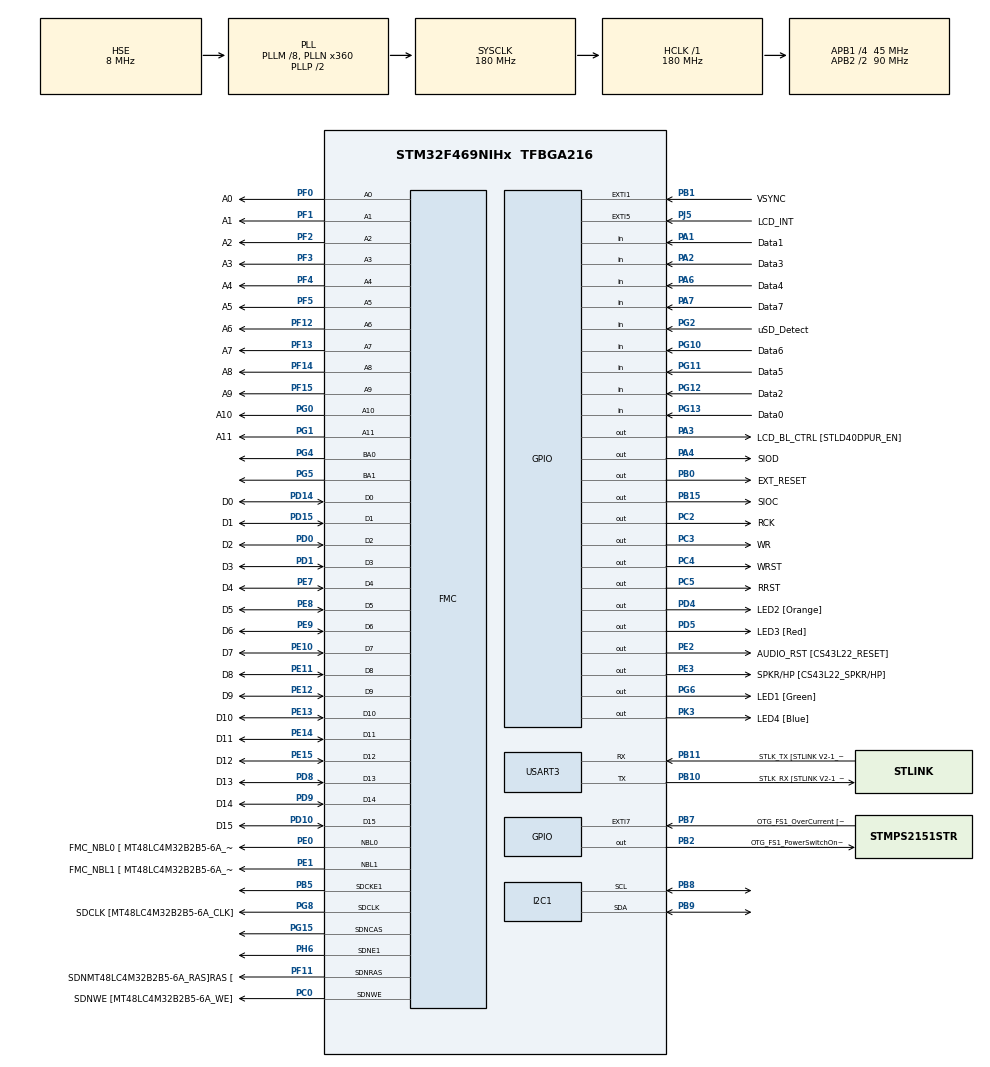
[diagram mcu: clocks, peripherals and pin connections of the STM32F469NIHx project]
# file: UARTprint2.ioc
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DSIHOST_CKN.GPIO_Label=DSI_CK_N
DSIHOST_CKN.Mode=DSIHost_Video
DSIHOST_CKN.Signal=DSIHOST_CKN
DSIHOST_CKP.GPIO_Label=DSI_CK_P
DSIHOST_CKP.Mode=DSIHost_Video
DSIHOST_CKP.Signal=DSIHOST_CKP
DSIHOST_D0N.GPIO_Label=DSI_D0_N
DSIHOST_D0N.Mode=DSIHost_Video
DSIHOST_D0N.Signal=DSIHOST_D0N
DSIHOST_D0P.GPIO_Label=DSI_D0_P
DSIHOST_D0P.Mode=DSIHost_Video
DSIHOST_D0P.Signal=DSIHOST_D0P
DSIHOST_D1N.GPIO_Label=DSI_D1_N
DSIHOST_D1N.Mode=DSIHost_Video
DSIHOST_D1N.Signal=DSIHOST_D1N
DSIHOST_D1P.GPIO_Label=DSI_D1_P
DSIHOST_D1P.Mode=DSIHost_Video
DSIHOST_D1P.Signal=DSIHOST_D1P
Mcu.Family=STM32F4
Mcu.Name=STM32F469NIHx
Mcu.Package=TFBGA216
NVIC.EXTI1_IRQn=true\:0\:0\:false\:false\:true\:true
NVIC.I2C1_EV_IRQn=true\:0\:0\:false\:false\:true\:true
NVIC.PriorityGroup=NVIC_PRIORITYGROUP_4
NVIC.USART3_IRQn=true\:0\:0\:false\:false\:true\:true
PA0/WKUP.GPIO_Label=WAKEUP [B2]
PA0/WKUP.Signal=SYS_WKUP
PA1.GPIO_Label=Data1
PA1.Signal=GPIO_Input
PA10.GPIO_Label=USB_FS1_ID
PA10.GPIO_Mode=GPIO_MODE_AF_PP
PA10.GPIO_PuPd=GPIO_NOPULL
PA10.GPIO_Speed=GPIO_SPEED_FREQ_VERY_HIGH
PA10.Signal=USB_OTG_FS_ID
PA11.GPIO_Label=USB_FS1_N
PA11.GPIO_Mode=GPIO_MODE_AF_PP
PA11.GPIO_PuPd=GPIO_NOPULL
PA11.GPIO_Speed=GPIO_SPEED_FREQ_VERY_HIGH
PA11.Signal=USB_OTG_FS_DM
PA12.GPIO_Label=USB_FS1_P
PA12.GPIO_Mode=GPIO_MODE_AF_PP
PA12.GPIO_PuPd=GPIO_NOPULL
PA12.GPIO_Speed=GPIO_SPEED_FREQ_VERY_HIGH
PA12.Signal=USB_OTG_FS_DP
PA13.GPIO_Label=SWDIO
PA13.Signal=SYS_JTMS-SWDIO
PA14.GPIO_Label=SWCLK
PA14.Signal=SYS_JTCK-SWCLK
PA2.GPIO_Label=Data3
PA2.Signal=GPIO_Input
PA3.GPIO_Label=LCD_BL_CTRL [STLD40DPUR_EN]
PA3.Signal=GPIO_Output
PA4.GPIO_Label=SIOD
PA4.GPIO_ModeDefaultOutputPP=GPIO_MODE_OUTPUT_OD
PA4.GPIO_PuPd=GPIO_PULLUP
PA4.GPIO_Speed=GPIO_SPEED_FREQ_HIGH
PA4.Signal=GPIO_Output
PA6.GPIO_Label=Data4
PA6.Signal=GPIO_Input
PA7.GPIO_Label=Data7
PA7.Signal=GPIO_Input
PA9.GPIO_Label=VBUS_FS1
PA9.GPIO_Mode=GPIO_MODE_AF_PP
PA9.GPIO_PuPd=GPIO_NOPULL
PA9.GPIO_Speed=GPIO_SPEED_FREQ_VERY_HIGH
PA9.Signal=USB_OTG_FS_VBUS
PB0.GPIO_Label=EXT_RESET
PB0.Signal=GPIO_Output
PB1.GPIO_Label=VSYNC
PB1.GPIO_ModeDefaultEXTI=GPIO_MODE_IT_FALLING
PB1.Signal=GPXTI1
PB10.GPIO_Label=STLK_RX [STLINK V2-1_U2_RX]
PB10.Mode=Asynchronous
PB10.Signal=USART3_TX
PB11.GPIO_Label=STLK_TX [STLINK V2-1_U2_TX]
PB11.Mode=Asynchronous
PB11.Signal=USART3_RX
PB15.GPIO_Label=SIOC
PB15.GPIO_ModeDefaultOutputPP=GPIO_MODE_OUTPUT_OD
PB15.GPIO_PuPd=GPIO_PULLUP
PB15.GPIO_Speed=GPIO_SPEED_FREQ_HIGH
PB15.Signal=GPIO_Output
PB2/BOOT1.GPIO_Label=OTG_FS1_PowerSwitchOn [STMPS2151STR_En]
PB2/BOOT1.Signal=GPIO_Output
PB3.GPIO_Label=I2S3_CK
PB3.GPIO_Mode=GPIO_MODE_AF_PP
PB3.GPIO_PuPd=GPIO_NOPULL
PB3.GPIO_Speed=GPIO_SPEED_FREQ_LOW
PB3.Signal=I2S3_CK
PB5.Mode=SdramChipSelect2_1
PB5.Signal=FMC_SDCKE1
PB6.GPIO_Label=QSPI_BK1_NCS [N25Q128A13EF840F_S]
PB6.GPIO_Mode=GPIO_MODE_AF_PP
PB6.GPIO_PuPd=GPIO_NOPULL
PB6.GPIO_Speed=GPIO_SPEED_FREQ_VERY_HIGH
PB6.Signal=QUADSPI_BK1_NCS
PB7.GPIO_Label=OTG_FS1_OverCurrent [STMPS2151STR_FAULT]
PB7.GPIO_ModeDefaultEXTI=GPIO_MODE_IT_RISING
PB7.GPIO_PuPd=GPIO_NOPULL
PB7.Signal=GPXTI7
PB8.Mode=I2C
PB8.Signal=I2C1_SCL
PB9.Mode=I2C
PB9.Signal=I2C1_SDA
PC0.GPIO_Label=SDNWE [MT48LC4M32B2B5-6A_WE]
PC0.Signal=FMC_SDNWE
PC10.GPIO_Label=uSD_D2
PC10.GPIO_Mode=GPIO_MODE_AF_PP
PC10.GPIO_PuPd=GPIO_NOPULL
PC10.GPIO_Speed_High_Default=GPIO_SPEED_FREQ_VERY_HIGH
PC10.Signal=SDIO_D2
PC11.GPIO_Label=uSD_D3
PC11.GPIO_Mode=GPIO_MODE_AF_PP
PC11.GPIO_PuPd=GPIO_NOPULL
PC11.GPIO_Speed_High_Default=GPIO_SPEED_FREQ_VERY_HIGH
PC11.Signal=SDIO_D3
PC12.GPIO_Label=uSD_CLK
PC12.GPIO_Mode=GPIO_MODE_AF_PP
PC12.GPIO_PuPd=GPIO_NOPULL
PC12.GPIO_Speed_High_Default=GPIO_SPEED_FREQ_VERY_HIGH
PC12.Signal=SDIO_CK
PC14/OSC32_IN.Signal=RCC_OSC32_IN
PC15/OSC32_OUT.Signal=RCC_OSC32_OUT
PC2.GPIO_Label=RCK
PC2.GPIO_Speed=GPIO_SPEED_FREQ_HIGH
PC2.Signal=GPIO_Output
PC3.GPIO_Label=WR
PC3.GPIO_Speed=GPIO_SPEED_FREQ_HIGH
PC3.Signal=GPIO_Output
PC4.GPIO_Label=WRST
PC4.GPIO_Speed=GPIO_SPEED_FREQ_HIGH
PC4.Signal=GPIO_Output
PC5.GPIO_Label=RRST
PC5.GPIO_Speed=GPIO_SPEED_FREQ_HIGH
PC5.Signal=GPIO_Output
PC8.GPIO_Label=uSD_D0
PC8.GPIO_Mode=GPIO_MODE_AF_PP
PC8.GPIO_PuPd=GPIO_NOPULL
PC8.GPIO_Speed_High_Default=GPIO_SPEED_FREQ_VERY_HIGH
PC8.Signal=SDIO_D0
PC9.GPIO_Label=uSD_D1
PC9.GPIO_Mode=GPIO_MODE_AF_PP
PC9.GPIO_PuPd=GPIO_NOPULL
PC9.GPIO_Speed_High_Default=GPIO_SPEED_FREQ_VERY_HIGH
PC9.Signal=SDIO_D1
PD0.GPIO_Label=D2
PD0.GPIO_Mode=GPIO_MODE_AF_PP
PD0.GPIO_PuPd=GPIO_NOPULL
PD0.GPIO_Speed_High_Default=GPIO_SPEED_FREQ_VERY_HIGH
PD0.Signal=FMC_D2_DA2
PD1.GPIO_Label=D3
PD1.GPIO_Mode=GPIO_MODE_AF_PP
PD1.GPIO_PuPd=GPIO_NOPULL
PD1.GPIO_Speed_High_Default=GPIO_SPEED_FREQ_VERY_HIGH
PD1.Signal=FMC_D3_DA3
PD10.GPIO_Label=D15
PD10.Signal=FMC_D15_DA15
PD13.GPIO_Label=MIC_CK [MP34DT01TR_CLK]
PD13.Signal=S_TIM4_CH2
PD14.GPIO_Label=D0
PD14.Signal=FMC_D0_DA0
PD15.GPIO_Label=D1
PD15.Signal=FMC_D1_DA1
PD2.GPIO_Label=uSD_CMD
PD2.GPIO_Mode=GPIO_MODE_AF_PP
PD2.GPIO_PuPd=GPIO_NOPULL
PD2.GPIO_Speed_High_Default=GPIO_SPEED_FREQ_VERY_HIGH
PD2.Signal=SDIO_CMD
PD4.GPIO_Label=LED2 [Orange]
PD4.GPIO_ModeDefaultOutputPP=GPIO_MODE_OUTPUT_OD
PD4.GPIO_PuPd=GPIO_NOPULL
PD4.GPIO_Speed=GPIO_SPEED_FREQ_LOW
PD4.Signal=GPIO_Output
PD5.GPIO_Label=LED3 [Red]
PD5.GPIO_ModeDefaultOutputPP=GPIO_MODE_OUTPUT_OD
PD5.GPIO_PuPd=GPIO_NOPULL
PD5.GPIO_Speed=GPIO_SPEED_FREQ_LOW
PD5.Signal=GPIO_Output
PD6.GPIO_Label=MIC_DATA [MP34DT01TR_DOUT]
PD6.GPIO_Mode=GPIO_MODE_AF_PP
PD6.GPIO_PuPd=GPIO_NOPULL
PD6.GPIO_Speed=GPIO_SPEED_FREQ_LOW
PD6.Signal=SAI1_SD_A
PD8.GPIO_Label=D13
PD8.Signal=FMC_D13_DA13
PD9.GPIO_Label=D14
PD9.Signal=FMC_D14_DA14
PE0.GPIO_Label=FMC_NBL0 [ MT48LC4M32B2B5-6A_DQM0]
PE0.GPIO_Mode=GPIO_MODE_AF_PP
PE0.GPIO_PuPd=GPIO_NOPULL
PE0.GPIO_Speed_High_Default=GPIO_SPEED_FREQ_VERY_HIGH
PE0.Signal=FMC_NBL0
PE1.GPIO_Label=FMC_NBL1 [ MT48LC4M32B2B5-6A_DQM1]
PE1.GPIO_Mode=GPIO_MODE_AF_PP
PE1.GPIO_PuPd=GPIO_NOPULL
PE1.GPIO_Speed_High_Default=GPIO_SPEED_FREQ_VERY_HIGH
PE1.Signal=FMC_NBL1
PE10.GPIO_Label=D7
PE10.Signal=FMC_D7_DA7
PE11.GPIO_Label=D8
PE11.Signal=FMC_D8_DA8
PE12.GPIO_Label=D9
PE12.Signal=FMC_D9_DA9
PE13.GPIO_Label=D10
PE13.Signal=FMC_D10_DA10
PE14.GPIO_Label=D11
PE14.Signal=FMC_D11_DA11
PE15.GPIO_Label=D12
PE15.Signal=FMC_D12_DA12
PE2.GPIO_Label=AUDIO_RST [CS43L22_RESET]
PE2.GPIO_ModeDefaultOutputPP=GPIO_MODE_OUTPUT_PP
PE2.GPIO_PuPd=GPIO_NOPULL
PE2.GPIO_Speed=GPIO_SPEED_FREQ_LOW
PE2.Signal=GPIO_Output
PE3.GPIO_Label=SPKR/HP [CS43L22_SPKR/HP]
PE3.GPIO_ModeDefaultOutputPP=GPIO_MODE_OUTPUT_PP
PE3.GPIO_PuPd=GPIO_NOPULL
PE3.GPIO_Speed=GPIO_SPEED_FREQ_LOW
PE3.Signal=GPIO_Output
PE4.GPIO_Label=SAI1_FSA [CS43L22_LRCK]
PE4.GPIO_Mode=GPIO_MODE_AF_PP
PE4.GPIO_PuPd=GPIO_NOPULL
PE4.GPIO_Speed=GPIO_SPEED_FREQ_LOW
PE4.Signal=SAI1_FS_A
PE5.GPIO_Label=SAI1_SCKA [CS43L22_CLK]
PE5.GPIO_Mode=GPIO_MODE_AF_PP
PE5.GPIO_PuPd=GPIO_NOPULL
PE5.GPIO_Speed=GPIO_SPEED_FREQ_LOW
PE5.Signal=SAI1_SCK_A
PE7.GPIO_Label=D4
PE7.Signal=FMC_D4_DA4
PE8.GPIO_Label=D5
PE8.Signal=FMC_D5_DA5
PE9.GPIO_Label=D6
PE9.Signal=FMC_D6_DA6
PF0.GPIO_Label=A0
PF0.GPIO_Mode=GPIO_MODE_AF_PP
PF0.GPIO_PuPd=GPIO_NOPULL
PF0.GPIO_Speed_High_Default=GPIO_SPEED_FREQ_VERY_HIGH
PF0.Signal=FMC_A0
PF1.GPIO_Label=A1
PF1.GPIO_Mode=GPIO_MODE_AF_PP
PF1.GPIO_PuPd=GPIO_NOPULL
PF1.GPIO_Speed_High_Default=GPIO_SPEED_FREQ_VERY_HIGH
PF1.Signal=FMC_A1
PF10.GPIO_Label=QSPI_CLK [N25Q128A13EF840F_C]
PF10.Signal=QUADSPI_CLK
PF11.GPIO_Label=SDNMT48LC4M32B2B5-6A_RAS]RAS [
PF11.Signal=FMC_SDNRAS
PF12.GPIO_Label=A6
PF12.Signal=FMC_A6
PF13.GPIO_Label=A7
PF13.Signal=FMC_A7
PF14.GPIO_Label=A8
PF14.Signal=FMC_A8
PF15.GPIO_Label=A9
PF15.Signal=FMC_A9
PF2.GPIO_Label=A2
PF2.GPIO_Mode=GPIO_MODE_AF_PP
PF2.GPIO_PuPd=GPIO_NOPULL
PF2.GPIO_Speed_High_Default=GPIO_SPEED_FREQ_VERY_HIGH
PF2.Signal=FMC_A2
PF3.GPIO_Label=A3
PF3.GPIO_Mode=GPIO_MODE_AF_PP
PF3.GPIO_PuPd=GPIO_NOPULL
PF3.GPIO_Speed_High_Default=GPIO_SPEED_FREQ_VERY_HIGH
PF3.Signal=FMC_A3
PF4.GPIO_Label=A4
PF4.GPIO_Mode=GPIO_MODE_AF_PP
PF4.GPIO_PuPd=GPIO_NOPULL
PF4.GPIO_Speed_High_Default=GPIO_SPEED_FREQ_VERY_HIGH
PF4.Signal=FMC_A4
PF5.GPIO_Label=A5
PF5.Signal=FMC_A5
PF6.GPIO_Label=QSPI_BK1_IO3 [N25Q128A13EF840F_DQ3]
PF6.Signal=QUADSPI_BK1_IO3
PF7.GPIO_Label=QSPI_BK1_IO2 [N25Q128A13EF840F_DQ2]
PF7.Signal=QUADSPI_BK1_IO2
PF8.GPIO_Label=QSPI_BK1_IO0 [N25Q128A13EF840F_DQ0]
PF8.Signal=QUADSPI_BK1_IO0
PF9.GPIO_Label=QSPI_BK1_IO1 [N25Q128A13EF840F_DQ1]
PF9.Signal=QUADSPI_BK1_IO1
PG0.GPIO_Label=A10
PG0.Signal=FMC_A10
PG1.GPIO_Label=A11
PG1.Signal=FMC_A11
PG10.GPIO_Label=Data6
PG10.Signal=GPIO_Input
PG11.GPIO_Label=Data5
PG11.Signal=GPIO_Input
PG12.GPIO_Label=Data2
PG12.Signal=GPIO_Input
PG13.GPIO_Label=Data0
PG13.Signal=GPIO_Input
PG14.GPIO_Label=ARDUINO USART6_TX
PG14.GPIO_Mode=GPIO_MODE_AF_PP
PG14.GPIO_PuPd=GPIO_NOPULL
PG14.GPIO_Speed=GPIO_SPEED_FREQ_VERY_HIGH
PG14.Signal=USART6_TX
PG15.Signal=FMC_SDNCAS
PG2.GPIO_Label=uSD_Detect
PG2.Signal=GPIO_Input
PG4.Signal=FMC_A14_BA0
PG5.Signal=FMC_A15_BA1
PG6.GPIO_Label=LED1 [Green]
PG6.GPIO_ModeDefaultOutputPP=GPIO_MODE_OUTPUT_OD
PG6.GPIO_PuPd=GPIO_NOPULL
PG6.GPIO_Speed=GPIO_SPEED_FREQ_LOW
PG6.Signal=GPIO_Output
PG7.GPIO_Label=SAI1_MCLKA [CS43L22_MCLK]
PG7.GPIO_Mode=GPIO_MODE_AF_PP
PG7.GPIO_PuPd=GPIO_NOPULL
PG7.GPIO_Speed=GPIO_SPEED_FREQ_LOW
PG7.Signal=SAI1_MCLK_A
PG8.GPIO_Label=SDCLK [MT48LC4M32B2B5-6A_CLK]
PG8.GPIO_Mode=GPIO_MODE_AF_PP
PG8.GPIO_PuPd=GPIO_NOPULL
PG8.GPIO_Speed_High_Default=GPIO_SPEED_FREQ_VERY_HIGH
PG8.Signal=FMC_SDCLK
PG9.GPIO_Label=USART6_RX
PG9.GPIO_Mode=GPIO_MODE_AF_PP
PG9.GPIO_PuPd=GPIO_NOPULL
PG9.GPIO_Speed=GPIO_SPEED_FREQ_VERY_HIGH
PG9.Signal=USART6_RX
PH0/OSC_IN.Mode=HSE-External-Oscillator
PH0/OSC_IN.Signal=RCC_OSC_IN
PH1/OSC_OUT.Mode=HSE-External-Oscillator
PH1/OSC_OUT.Signal=RCC_OSC_OUT
PH10.GPIO_Label=D18
PH10.Signal=FMC_D18
PH11.GPIO_Label=D19
PH11.Signal=FMC_D19
PH12.GPIO_Label=D20
PH12.Signal=FMC_D20
PH13.GPIO_Label=D21
PH13.GPIO_Mode=GPIO_MODE_AF_PP
PH13.GPIO_PuPd=GPIO_NOPULL
PH13.GPIO_Speed_High_Default=GPIO_SPEED_FREQ_VERY_HIGH
PH13.Signal=FMC_D21
PH14.GPIO_Label=D22
PH14.GPIO_Mode=GPIO_MODE_AF_PP
PH14.GPIO_PuPd=GPIO_NOPULL
PH14.GPIO_Speed_High_Default=GPIO_SPEED_FREQ_VERY_HIGH
PH14.Signal=FMC_D22
PH15.GPIO_Label=D23
PH15.GPIO_Mode=GPIO_MODE_AF_PP
PH15.GPIO_PuPd=GPIO_NOPULL
PH15.GPIO_Speed_High_Default=GPIO_SPEED_FREQ_VERY_HIGH
PH15.Signal=FMC_D23
PH2.GPIO_Label=SDCKE0 [MT48LC4M32B2B5-6A_CKE]
PH2.Signal=FMC_SDCKE0
PH3.GPIO_Label=SDNE0 [MT48LC4M32B2B5-6A_CS]
PH3.GPIO_Mode=GPIO_MODE_AF_PP
PH3.GPIO_PuPd=GPIO_NOPULL
PH3.GPIO_Speed_High_Default=GPIO_SPEED_FREQ_VERY_HIGH
PH3.Signal=FMC_SDNE0
PH4.GPIO_Label=I2C2_SCL [CS43L22_SCL]
PH4.GPIO_Mode=GPIO_MODE_AF_OD
PH4.GPIO_PuPdOD=GPIO_PULLUP
PH4.GPIO_Speed=GPIO_SPEED_FREQ_VERY_HIGH
PH4.Signal=I2C2_SCL
PH5.GPIO_Label=I2C2_SDA [CS43L22_SDA]
PH5.GPIO_Mode=GPIO_MODE_AF_OD
PH5.GPIO_PuPdOD=GPIO_PULLUP
PH5.GPIO_Speed=GPIO_SPEED_FREQ_VERY_HIGH
PH5.Signal=I2C2_SDA
PH6.Mode=SdramChipSelect2_1
PH6.Signal=FMC_SDNE1
PH8.GPIO_Label=D16
PH8.Signal=FMC_D16
PH9.GPIO_Label=D17
PH9.Signal=FMC_D17
PI0.GPIO_Label=D24
PI0.GPIO_Mode=GPIO_MODE_AF_PP
PI0.GPIO_PuPd=GPIO_NOPULL
PI0.GPIO_Speed_High_Default=GPIO_SPEED_FREQ_VERY_HIGH
PI0.Signal=FMC_D24
PI1.GPIO_Label=D25
PI1.GPIO_Mode=GPIO_MODE_AF_PP
PI1.GPIO_PuPd=GPIO_NOPULL
PI1.GPIO_Speed_High_Default=GPIO_SPEED_FREQ_VERY_HIGH
PI1.Signal=FMC_D25
PI10.GPIO_Label=D31
PI10.GPIO_Mode=GPIO_MODE_AF_PP
PI10.GPIO_PuPd=GPIO_NOPULL
PI10.GPIO_Speed_High_Default=GPIO_SPEED_FREQ_VERY_HIGH
PI10.Signal=FMC_D31
PI2.GPIO_Label=D26
PI2.GPIO_Mode=GPIO_MODE_AF_PP
PI2.GPIO_PuPd=GPIO_NOPULL
PI2.GPIO_Speed_High_Default=GPIO_SPEED_FREQ_VERY_HIGH
PI2.Signal=FMC_D26
PI3.GPIO_Label=D27
PI3.GPIO_Mode=GPIO_MODE_AF_PP
PI3.GPIO_PuPd=GPIO_NOPULL
PI3.GPIO_Speed_High_Default=GPIO_SPEED_FREQ_VERY_HIGH
PI3.Signal=FMC_D27
PI4.GPIO_Label=FMC_NBL2 [MT48LC4M32B2B5-6A_DQM2]
PI4.GPIO_Mode=GPIO_MODE_AF_PP
PI4.GPIO_PuPd=GPIO_NOPULL
PI4.GPIO_Speed_High_Default=GPIO_SPEED_FREQ_VERY_HIGH
PI4.Signal=FMC_NBL2
PI5.GPIO_Label=FMC_NBL3 [MT48LC4M32B2B5-6A_DQM3]
PI5.GPIO_Mode=GPIO_MODE_AF_PP
PI5.GPIO_PuPd=GPIO_NOPULL
PI5.GPIO_Speed_High_Default=GPIO_SPEED_FREQ_VERY_HIGH
PI5.Signal=FMC_NBL3
PI6.GPIO_Label=D28
PI6.GPIO_Mode=GPIO_MODE_AF_PP
PI6.GPIO_PuPd=GPIO_NOPULL
PI6.GPIO_Speed_High_Default=GPIO_SPEED_FREQ_VERY_HIGH
PI6.Signal=FMC_D28
PI7.GPIO_Label=D29
PI7.GPIO_Mode=GPIO_MODE_AF_PP
PI7.GPIO_PuPd=GPIO_NOPULL
PI7.GPIO_Speed_High_Default=GPIO_SPEED_FREQ_VERY_HIGH
PI7.Signal=FMC_D29
PI9.GPIO_Label=D30
PI9.GPIO_Mode=GPIO_MODE_AF_PP
PI9.GPIO_PuPd=GPIO_NOPULL
PI9.GPIO_Speed_High_Default=GPIO_SPEED_FREQ_VERY_HIGH
PI9.Signal=FMC_D30
PJ2.GPIO_Label=DSI_TE
PJ2.Signal=DSIHOST_TE
PJ5.GPIO_Label=LCD_INT
PJ5.Signal=GPXTI5
PK3.GPIO_Label=LED4 [Blue]
PK3.GPIO_ModeDefaultOutputPP=GPIO_MODE_OUTPUT_OD
PK3.GPIO_PuPd=GPIO_NOPULL
PK3.GPIO_Speed=GPIO_SPEED_FREQ_LOW
PK3.Signal=GPIO_Output
ProjectManager.HeapSize=0x200
ProjectManager.StackSize=0x400
ProjectManager.TargetToolchain=MDK-ARM V5
RCC.AHBFreq_Value=180000000
RCC.APB1CLKDivider=RCC_HCLK_DIV4
RCC.APB1Freq_Value=45000000
RCC.APB1TimFreq_Value=90000000
RCC.APB2CLKDivider=RCC_HCLK_DIV2
RCC.APB2Freq_Value=90000000
RCC.APB2TimFreq_Value=180000000
RCC.CortexFreq_Value=180000000
RCC.HCLKFreq_Value=180000000
RCC.HSE_VALUE=8000000
RCC.PLLDSINDIV=62
RCC.PLLM=8
RCC.PLLN=360
RCC.PLLSourceVirtual=RCC_PLLSOURCE_HSE
RCC.SYSCLKFreq_VALUE=180000000
RCC.SYSCLKSource=RCC_SYSCLKSOURCE_PLLCLK
RCC.USBFreq_Value=90000000
RCC.VCOOutputFreq_Value=360000000
SH.FMC_A0.0=FMC_A0,12b-sda1
SH.FMC_A1.0=FMC_A1,12b-sda1
SH.FMC_A10.0=FMC_A10,12b-sda1
SH.FMC_A11.0=FMC_A11,12b-sda1
SH.FMC_A14_BA0.0=FMC_BA0,FourSdramBanks1
SH.FMC_A15_BA1.0=FMC_BA1,FourSdramBanks1
SH.FMC_A2.0=FMC_A2,12b-sda1
SH.FMC_A3.0=FMC_A3,12b-sda1
SH.FMC_A4.0=FMC_A4,12b-sda1
SH.FMC_A5.0=FMC_A5,12b-sda1
SH.FMC_A6.0=FMC_A6,12b-sda1
SH.FMC_A7.0=FMC_A7,12b-sda1
SH.FMC_A8.0=FMC_A8,12b-sda1
SH.FMC_A9.0=FMC_A9,12b-sda1
SH.FMC_D0_DA0.0=FMC_D0,sd-16b-d1
SH.FMC_D10_DA10.0=FMC_D10,sd-16b-d1
SH.FMC_D11_DA11.0=FMC_D11,sd-16b-d1
SH.FMC_D12_DA12.0=FMC_D12,sd-16b-d1
SH.FMC_D13_DA13.0=FMC_D13,sd-16b-d1
SH.FMC_D14_DA14.0=FMC_D14,sd-16b-d1
SH.FMC_D15_DA15.0=FMC_D15,sd-16b-d1
SH.FMC_D16.0=FMC_D16
SH.FMC_D17.0=FMC_D17
SH.FMC_D18.0=FMC_D18
SH.FMC_D19.0=FMC_D19
SH.FMC_D1_DA1.0=FMC_D1,sd-16b-d1
SH.FMC_D20.0=FMC_D20
SH.FMC_D21.0=FMC_D21
SH.FMC_D22.0=FMC_D22
SH.FMC_D23.0=FMC_D23
SH.FMC_D24.0=FMC_D24
SH.FMC_D25.0=FMC_D25
SH.FMC_D26.0=FMC_D26
SH.FMC_D27.0=FMC_D27
SH.FMC_D28.0=FMC_D28
SH.FMC_D29.0=FMC_D29
SH.FMC_D2_DA2.0=FMC_D2,sd-16b-d1
SH.FMC_D30.0=FMC_D30
SH.FMC_D31.0=FMC_D31
SH.FMC_D3_DA3.0=FMC_D3,sd-16b-d1
SH.FMC_D4_DA4.0=FMC_D4,sd-16b-d1
SH.FMC_D5_DA5.0=FMC_D5,sd-16b-d1
SH.FMC_D6_DA6.0=FMC_D6,sd-16b-d1
SH.FMC_D7_DA7.0=FMC_D7,sd-16b-d1
SH.FMC_D8_DA8.0=FMC_D8,sd-16b-d1
SH.FMC_D9_DA9.0=FMC_D9,sd-16b-d1
SH.FMC_NBL0.0=FMC_NBL0,Sd2ByteEnable1
SH.FMC_NBL1.0=FMC_NBL1,Sd2ByteEnable1
SH.FMC_NBL2.0=FMC_NBL2
SH.FMC_NBL3.0=FMC_NBL3
SH.FMC_SDCLK.0=FMC_SDCLK,12b-sda1
SH.FMC_SDNCAS.0=FMC_SDNCAS,12b-sda1
SH.FMC_SDNRAS.0=FMC_SDNRAS,12b-sda1
SH.FMC_SDNWE.0=FMC_SDNWE,12b-sda1
SH.S_TIM4_CH2.0=TIM4_CH2
USART3.VirtualMode=VM_ASYNC
VP_DMA2D_VS_DMA2D.Mode=DMA2D_Activate
VP_LTDC_DSIMode.Mode=RGB565
board=32F469IDISCOVERY

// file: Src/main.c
/**
  ******************************************************************************
  * @file           : main.c
  * @brief          : Main program body
  ******************************************************************************
  ** This notice applies to any and all portions of this file
  * that are not between comment pairs USER CODE BEGIN and
  * USER CODE END. Other portions of this file, whether
  * inserted by the user or by software development tools
  * are owned by their respective copyright owners.
  *
  * COPYRIGHT(c) 2018 STMicroelectronics
  *
  * Redistribution and use in source and binary forms, with or without modification,
  * are permitted provided that the following conditions are met:
  *   1. Redistributions of source code must retain the above copyright notice,
  *      this list of conditions and the following disclaimer.
  *   2. Redistributions in binary form must reproduce the above copyright notice,
  *      this list of conditions and the following disclaimer in the documentation
  *      and/or other materials provided with the distribution.
  *   3. Neither the name of STMicroelectronics nor the names of its contributors
  *      may be used to endorse or promote products derived from this software
  *      without specific prior written permission.
  *
  * THIS SOFTWARE IS PROVIDED BY THE COPYRIGHT HOLDERS AND CONTRIBUTORS "AS IS"
  * AND ANY EXPRESS OR IMPLIED WARRANTIES, INCLUDING, BUT NOT LIMITED TO, THE
  * IMPLIED WARRANTIES OF MERCHANTABILITY AND FITNESS FOR A PARTICULAR PURPOSE ARE
  * DISCLAIMED. IN NO EVENT SHALL THE COPYRIGHT HOLDER OR CONTRIBUTORS BE LIABLE
  * FOR ANY DIRECT, INDIRECT, INCIDENTAL, SPECIAL, EXEMPLARY, OR CONSEQUENTIAL
  * DAMAGES (INCLUDING, BUT NOT LIMITED TO, PROCUREMENT OF SUBSTITUTE GOODS OR
  * SERVICES; LOSS OF USE, DATA, OR PROFITS; OR BUSINESS INTERRUPTION) HOWEVER
  * CAUSED AND ON ANY THEORY OF LIABILITY, WHETHER IN CONTRACT, STRICT LIABILITY,
  * OR TORT (INCLUDING NEGLIGENCE OR OTHERWISE) ARISING IN ANY WAY OUT OF THE USE
  * OF THIS SOFTWARE, EVEN IF ADVISED OF THE POSSIBILITY OF SUCH DAMAGE.
  *
  ******************************************************************************
  */
#include "main.h"
#include "stm32f4xx_hal.h"

/* USER CODE BEGIN Includes */
#include "stm32469i_discovery.h"
#include "stm32469i_discovery_lcd.h"
#include "SCCB.h"
#include "OV7670.h"

/* USER CODE END Includes */

DMA2D_HandleTypeDef hdma2d;

DSI_HandleTypeDef hdsi;

I2C_HandleTypeDef hi2c1;

LTDC_HandleTypeDef hltdc;

UART_HandleTypeDef huart3;

SDRAM_HandleTypeDef hsdram1;

/* USER CODE BEGIN PV */
/* Private variables ---------------------------------------------------------*/

/* USER CODE END PV */

void SystemClock_Config(void);
static void MX_GPIO_Init(void);
static void MX_USART3_UART_Init(void);
static void MX_I2C1_Init(void);
static void MX_LTDC_Init(void);
static void MX_DMA2D_Init(void);
static void MX_DSIHOST_DSI_Init(void);
static void MX_FMC_Init(void);

/* USER CODE BEGIN PFP */
/* Private function prototypes -----------------------------------------------*/

/* USER CODE END PFP */

/* USER CODE BEGIN 0 */
uint32_t count=0;
uint32_t vsyncCount=(uint32_t)'0';
uint32_t vsyncStatus=0;
uint32_t photoTakeTimeStart=0;
uint32_t photoTakeTimeEnd=0;
uint32_t photoTakeTimeElapse=0;
char photoTakeTimeElapseHex[6];
uint8_t Data[8];
/**
  * @brief  Retargets the C library printf function to the UART.
	* @param  None
	* @retval None
  */
#ifdef __GNUC__
	#define PUTCHAR_PROTOTYPE int __io_putchar(int ch)
#else
	#define PUTCHAR_PROTOTYPE int fputc(int ch, FILE *f)
#endif

PUTCHAR_PROTOTYPE
{
	HAL_UART_Transmit(&huart3, (uint8_t *)&ch, 1, 0xFFFF);
	return ch;
}

/* USER CODE END 0 */

int main(void)
{

  /* MCU Configuration----------------------------------------------------------*/

  /* Reset of all peripherals, Initializes the Flash interface and the Systick. */
  HAL_Init();

  /* USER CODE BEGIN Init */

	BSP_LED_Init(LED1);
	BSP_LED_Init(LED2);
	BSP_LED_Init(LED3);
	BSP_LED_Init(LED4);

  /* USER CODE END Init */

  /* Configure the system clock */
  SystemClock_Config();

  /* USER CODE BEGIN SysInit */
	uint8_t Container[2] = {0x44, 0xAA};
	char ContainerInHex[2];
  /* USER CODE END SysInit */

  /* Initialize all configured peripherals */
  MX_GPIO_Init();
  MX_USART3_UART_Init();
  MX_I2C1_Init();
  MX_LTDC_Init();
  MX_DMA2D_Init();
  MX_DSIHOST_DSI_Init();
  MX_FMC_Init();
  /* USER CODE BEGIN 2 */
	I2C_WriteByte(0x12, 0x80, ADDR_OV7670);
	HAL_Delay(50);
//	I2C_WriteByte(0x12, 0x14, ADDR_OV7670);
	HAL_Delay(50);
	//Sensor_Init();

	I2C_ReadByte(Container, 1, 0x12, ADDR_OV7670);
	printf("0x12:%X\n\r", Container[0]);

	for(uint8_t i=0; i<202; i++)
	{
		I2C_ReadByte(Container, 1, i, ADDR_OV7670);
		printf("%X:%X\n\r",i, Container[0]);
		HAL_Delay(10);
	}
	BSP_LCD_Init();
	BSP_LCD_LayerDefaultInit(0, LCD_FB_START_ADDRESS);
	BSP_LCD_SelectLayer(0);
	BSP_LCD_Clear(LCD_COLOR_WHITE);

	//WE_H();

	WRST_H();
	RRST_H();

  /* USER CODE END 2 */

  /* Infinite loop */
  while (1)
  {

  /* USER CODE BEGIN 3 */
//		I2C_ReadByte(Container, 1, 0x11, ADDR_OV7670);
//		HAL_Delay(100);
//		HAL_UART_Transmit(&huart3, (uint8_t*) "It's Working", 12, 0XFFFF);
//		ContainerInHex[0]=Container[0]/16+'0';
//		ContainerInHex[1]=Container[0]%16+'0';
//		HAL_UART_Transmit(&huart3, (uint8_t*)ContainerInHex, 2, 0xFFFF);
//		HAL_UART_Transmit(&huart3, (uint8_t*) "\r\n", 4, 0xFFFF);
//		HAL_UART_Transmit(&huart3, (uint8_t*)&vsyncCount, 1, 0xFFFF);
//		HAL_UART_Transmit(&huart3, (uint8_t*) "\r\n", 4, 0xFFFF);
//		for(int i=5; i>=0; i--)
//		{
//			photoTakeTimeElapseHex[i]=photoTakeTimeElapse%16+'0';
//			photoTakeTimeElapse/=16;
//		}
//		if(vsyncStatus==1) HAL_UART_Transmit(&huart3, (uint8_t*)"Interrupted\r\n", 15, 0xFFFF);

//		HAL_UART_Transmit(&huart3, (uint8_t*)photoTakeTimeElapseHex, 6, 0xFFFF);
//		HAL_UART_Transmit(&huart3, (uint8_t*) "\r\n", 4, 0xFFFF);

		if( vsyncStatus == 2 )
		{
//			HAL_UART_Transmit(&huart3, (uint8_t*)"It can turn into 2\n\r", 22, 0xFFFF);
			//WE_L();
			RRST_L();
			RCLK_L();

			for(int i=0; i<100	; i++);

			RCLK_H();
			RRST_H();
			RCLK_L();
			for(int i=0; i<100; i++);

			RCLK_H();
			for(int i=0; i<100; i++);

//			for( count = 0; count < 76800; count++ )
//			{
			for(int yAxis=0; yAxis<240; yAxis++)
			{
				for(int xAxis=0; xAxis<320; xAxis++)
				{
					RCLK_L();

					uint8_t tmpData = 0x00;
					uint32_t redVal=0x00, greenVal=0x00, blueVal=0x00;
					uint8_t tmpDataHex[2];
					uint32_t mixed=0xFF000000;

					redVal |=	 ((Data3_GPIO_Port->IDR & Data3_Pin)>>2)
										|((Data4_GPIO_Port->IDR & Data4_Pin)>>5)
										|((Data5_GPIO_Port->IDR & Data5_Pin)>>9)
										|((Data3_GPIO_Port->IDR & Data3_Pin)<<1)
										|((Data4_GPIO_Port->IDR & Data4_Pin)>>2)
										|((Data5_GPIO_Port->IDR & Data5_Pin)>>6)
										|((Data6_GPIO_Port->IDR & Data6_Pin)>>4)
										|((Data7_GPIO_Port->IDR & Data7_Pin));

					greenVal |=	 (Data0_GPIO_Port->IDR & Data0_Pin>>8)
											|((Data1_GPIO_Port->IDR & Data1_Pin)<<5)
											|((Data2_GPIO_Port->IDR & Data2_Pin)>>5);

	//				tmpData |= (Data0_GPIO_Port->IDR & Data0_Pin>>13)
	//									|((Data1_GPIO_Port->IDR & Data1_Pin))
	//									|((Data2_GPIO_Port->IDR & Data2_Pin)>>10)
	//									|((Data3_GPIO_Port->IDR & Data3_Pin)<<1)
	//									|((Data4_GPIO_Port->IDR & Data4_Pin)>>2)
	//									|((Data5_GPIO_Port->IDR & Data5_Pin)>>6)
	//									|((Data6_GPIO_Port->IDR & Data6_Pin)>>4)
	//									|((Data7_GPIO_Port->IDR & Data7_Pin));	  /* ( GPIO_ReadInputData(GPIOC) << 8 ) & 0xff00; */

	//				printf("1:");
	//				if(Data0_GPIO_Port->IDR&Data0_Pin) printf("1"); else printf("0");
	//				if(Data1_GPIO_Port->IDR&Data1_Pin) printf("1"); else printf("0");
	//				if(Data2_GPIO_Port->IDR&Data2_Pin) printf("1"); else printf("0");
	//				if(Data3_GPIO_Port->IDR&Data3_Pin) printf("1"); else printf("0");
	//				if(Data4_GPIO_Port->IDR&Data4_Pin) printf("1"); else printf("0");
	//				if(Data5_GPIO_Port->IDR&Data5_Pin) printf("1"); else printf("0");
	//				if(Data6_GPIO_Port->IDR&Data6_Pin) printf("1"); else printf("0");
	//				if(Data7_GPIO_Port->IDR&Data7_Pin) printf("1"); else printf("0");
	//				printf("\r\n");
					RCLK_H();

	//				tmpDataHex[0]=tmpData/16+'0';
	//				tmpDataHex[1]=tmpData%16+'0';
					//HAL_UART_Transmit(&huart3, tmpDataHex, 2, 0xFFFF);
					for(int i=0; i<100; i++);

					RCLK_L();
	//				tmpData=0x00;
	//				tmpData |= (Data0_GPIO_Port->IDR & Data0_Pin>>13)
	//									|((Data1_GPIO_Port->IDR & Data1_Pin))
	//									|((Data2_GPIO_Port->IDR & Data2_Pin)>>10)
	//									|((Data3_GPIO_Port->IDR & Data3_Pin)<<1)
	//									|((Data4_GPIO_Port->IDR & Data4_Pin)>>2)
	//									|((Data5_GPIO_Port->IDR & Data5_Pin)>>6)
	//									|((Data6_GPIO_Port->IDR & Data6_Pin)>>4)
	//									|((Data7_GPIO_Port->IDR & Data7_Pin));	  /* ( GPIO_ReadInputData(GPIOC) ) & 0x00ff; */
					greenVal |=  ((Data6_GPIO_Port->IDR & Data6_Pin)>>10)
											|((Data7_GPIO_Port->IDR & Data7_Pin)>>6)
											|((Data5_GPIO_Port->IDR & Data5_Pin)>>9)
											|((Data6_GPIO_Port->IDR & Data6_Pin)>>7)
											|((Data7_GPIO_Port->IDR & Data7_Pin)>>3);

					blueVal |=   ((Data0_GPIO_Port->IDR & Data0_Pin)>>13)
											|((Data1_GPIO_Port->IDR & Data1_Pin))
											|((Data2_GPIO_Port->IDR & Data2_Pin)>>10)
											|((Data0_GPIO_Port->IDR & Data0_Pin)>>10)
											|((Data1_GPIO_Port->IDR & Data1_Pin)<<3)
											|((Data2_GPIO_Port->IDR & Data2_Pin)>>7)
											|((Data3_GPIO_Port->IDR & Data3_Pin)<<4)
											|((Data4_GPIO_Port->IDR & Data4_Pin)<<1);

					mixed |= 0xff000000|redVal<<16 | greenVal<<8 | blueVal;
					BSP_LCD_DrawPixel(xAxis, yAxis, mixed);
					RCLK_H();
				}
			}

//				tmpDataHex[0]=tmpData/16+'0';
//				tmpDataHex[1]=tmpData%16+'0';
				//HAL_UART_Transmit(&huart3, tmpDataHex, 2, 0xFFFF);

			//}
			//HAL_UART_Transmit(&huart3, (uint8_t*)"\r\n", 4, 0xFFFF);
			//WE_L();
			RCLK_L();
			WRST_L();
			RRST_L();
			for(int i=0; i<100; i++);
			WRST_H();
			RRST_H();

			vsyncStatus = 0;
    }

		if(count>500)
		{
			count=0;
			BSP_LED_Toggle(LED1);
		}

  }
  /* USER CODE END 3 */

}

void SystemClock_Config(void)
{

  RCC_OscInitTypeDef RCC_OscInitStruct;
  RCC_ClkInitTypeDef RCC_ClkInitStruct;
  RCC_PeriphCLKInitTypeDef PeriphClkInitStruct;

    /**Configure the main internal regulator output voltage
    */
  __HAL_RCC_PWR_CLK_ENABLE();

  __HAL_PWR_VOLTAGESCALING_CONFIG(PWR_REGULATOR_VOLTAGE_SCALE1);

    /**Initializes the CPU, AHB and APB busses clocks
    */
  RCC_OscInitStruct.OscillatorType = RCC_OSCILLATORTYPE_HSE;
  RCC_OscInitStruct.HSEState = RCC_HSE_ON;
  RCC_OscInitStruct.PLL.PLLState = RCC_PLL_ON;
  RCC_OscInitStruct.PLL.PLLSource = RCC_PLLSOURCE_HSE;
  RCC_OscInitStruct.PLL.PLLM = 8;
  RCC_OscInitStruct.PLL.PLLN = 360;
  RCC_OscInitStruct.PLL.PLLP = RCC_PLLP_DIV2;
  RCC_OscInitStruct.PLL.PLLQ = 4;
  RCC_OscInitStruct.PLL.PLLR = 2;
  if (HAL_RCC_OscConfig(&RCC_OscInitStruct) != HAL_OK)
  {
    _Error_Handler(__FILE__, __LINE__);
  }

    /**Activate the Over-Drive mode
    */
  if (HAL_PWREx_EnableOverDrive() != HAL_OK)
  {
    _Error_Handler(__FILE__, __LINE__);
  }

    /**Initializes the CPU, AHB and APB busses clocks
    */
  RCC_ClkInitStruct.ClockType = RCC_CLOCKTYPE_HCLK|RCC_CLOCKTYPE_SYSCLK
                              |RCC_CLOCKTYPE_PCLK1|RCC_CLOCKTYPE_PCLK2;
  RCC_ClkInitStruct.SYSCLKSource = RCC_SYSCLKSOURCE_PLLCLK;
  RCC_ClkInitStruct.AHBCLKDivider = RCC_SYSCLK_DIV1;
  RCC_ClkInitStruct.APB1CLKDivider = RCC_HCLK_DIV4;
  RCC_ClkInitStruct.APB2CLKDivider = RCC_HCLK_DIV2;

  if (HAL_RCC_ClockConfig(&RCC_ClkInitStruct, FLASH_LATENCY_5) != HAL_OK)
  {
    _Error_Handler(__FILE__, __LINE__);
  }

  PeriphClkInitStruct.PeriphClockSelection = RCC_PERIPHCLK_LTDC;
  PeriphClkInitStruct.PLLSAI.PLLSAIN = 192;
  PeriphClkInitStruct.PLLSAI.PLLSAIR = 2;
  PeriphClkInitStruct.PLLSAIDivR = RCC_PLLSAIDIVR_2;
  if (HAL_RCCEx_PeriphCLKConfig(&PeriphClkInitStruct) != HAL_OK)
  {
    _Error_Handler(__FILE__, __LINE__);
  }

    /**Configure the Systick interrupt time
    */
  HAL_SYSTICK_Config(HAL_RCC_GetHCLKFreq()/1000);

    /**Configure the Systick
    */
  HAL_SYSTICK_CLKSourceConfig(SYSTICK_CLKSOURCE_HCLK);

  /* SysTick_IRQn interrupt configuration */
  HAL_NVIC_SetPriority(SysTick_IRQn, 0, 0);
}

/* DMA2D init function */
static void MX_DMA2D_Init(void)
{

  hdma2d.Instance = DMA2D;
  hdma2d.Init.Mode = DMA2D_M2M;
  hdma2d.Init.ColorMode = DMA2D_OUTPUT_ARGB8888;
  hdma2d.Init.OutputOffset = 0;
  hdma2d.LayerCfg[1].InputOffset = 0;
  hdma2d.LayerCfg[1].InputColorMode = DMA2D_INPUT_ARGB8888;
  hdma2d.LayerCfg[1].AlphaMode = DMA2D_NO_MODIF_ALPHA;
  hdma2d.LayerCfg[1].InputAlpha = 0;
  if (HAL_DMA2D_Init(&hdma2d) != HAL_OK)
  {
    _Error_Handler(__FILE__, __LINE__);
  }

  if (HAL_DMA2D_ConfigLayer(&hdma2d, 1) != HAL_OK)
  {
    _Error_Handler(__FILE__, __LINE__);
  }

}

/* DSIHOST init function */
static void MX_DSIHOST_DSI_Init(void)
{

  DSI_PLLInitTypeDef PLLInit;
  DSI_HOST_TimeoutTypeDef HostTimeouts;
  DSI_PHY_TimerTypeDef PhyTimings;
  DSI_VidCfgTypeDef VidCfg;

  hdsi.Instance = DSI;
  hdsi.Init.AutomaticClockLaneControl = DSI_AUTO_CLK_LANE_CTRL_DISABLE;
  hdsi.Init.TXEscapeCkdiv = 4;
  hdsi.Init.NumberOfLanes = DSI_ONE_DATA_LANE;
  PLLInit.PLLNDIV = 62;
  PLLInit.PLLIDF = DSI_PLL_IN_DIV1;
  PLLInit.PLLODF = DSI_PLL_OUT_DIV1;
  if (HAL_DSI_Init(&hdsi, &PLLInit) != HAL_OK)
  {
    _Error_Handler(__FILE__, __LINE__);
  }

  HostTimeouts.TimeoutCkdiv = 1;
  HostTimeouts.HighSpeedTransmissionTimeout = 0;
  HostTimeouts.LowPowerReceptionTimeout = 0;
  HostTimeouts.HighSpeedReadTimeout = 0;
  HostTimeouts.LowPowerReadTimeout = 0;
  HostTimeouts.HighSpeedWriteTimeout = 0;
  HostTimeouts.HighSpeedWritePrespMode = DSI_HS_PM_DISABLE;
  HostTimeouts.LowPowerWriteTimeout = 0;
  HostTimeouts.BTATimeout = 0;
  if (HAL_DSI_ConfigHostTimeouts(&hdsi, &HostTimeouts) != HAL_OK)
  {
    _Error_Handler(__FILE__, __LINE__);
  }

  PhyTimings.ClockLaneHS2LPTime = 28;
  PhyTimings.ClockLaneLP2HSTime = 33;
  PhyTimings.DataLaneHS2LPTime = 15;
  PhyTimings.DataLaneLP2HSTime = 25;
  PhyTimings.DataLaneMaxReadTime = 0;
  PhyTimings.StopWaitTime = 0;
  if (HAL_DSI_ConfigPhyTimer(&hdsi, &PhyTimings) != HAL_OK)
  {
    _Error_Handler(__FILE__, __LINE__);
  }

  if (HAL_DSI_ConfigFlowControl(&hdsi, DSI_FLOW_CONTROL_BTA) != HAL_OK)
  {
    _Error_Handler(__FILE__, __LINE__);
  }

  if (HAL_DSI_SetLowPowerRXFilter(&hdsi, 10000) != HAL_OK)
  {
    _Error_Handler(__FILE__, __LINE__);
  }

  if (HAL_DSI_ConfigErrorMonitor(&hdsi, HAL_DSI_ERROR_NONE) != HAL_OK)
  {
    _Error_Handler(__FILE__, __LINE__);
  }

  VidCfg.VirtualChannelID = 0;
  VidCfg.ColorCoding = DSI_RGB565;
  VidCfg.LooselyPacked = DSI_LOOSELY_PACKED_DISABLE;
  VidCfg.Mode = DSI_VID_MODE_NB_PULSES;
  VidCfg.PacketSize = 1;
  VidCfg.NumberOfChunks = 640;
  VidCfg.NullPacketSize = 0;
  VidCfg.HSPolarity = DSI_HSYNC_ACTIVE_LOW;
  VidCfg.VSPolarity = DSI_VSYNC_ACTIVE_LOW;
  VidCfg.DEPolarity = DSI_DATA_ENABLE_ACTIVE_HIGH;
  VidCfg.HorizontalSyncActive = 10;
  VidCfg.HorizontalBackPorch = 9;
  VidCfg.HorizontalLine = 854;
  VidCfg.VerticalSyncActive = 4;
  VidCfg.VerticalBackPorch = 2;
  VidCfg.VerticalFrontPorch = 2;
  VidCfg.VerticalActive = 480;
  VidCfg.LPCommandEnable = DSI_LP_COMMAND_DISABLE;
  VidCfg.LPLargestPacketSize = 0;
  VidCfg.LPVACTLargestPacketSize = 0;
  VidCfg.LPHorizontalFrontPorchEnable = DSI_LP_HFP_DISABLE;
  VidCfg.LPHorizontalBackPorchEnable = DSI_LP_HBP_DISABLE;
  VidCfg.LPVerticalActiveEnable = DSI_LP_VACT_DISABLE;
  VidCfg.LPVerticalFrontPorchEnable = DSI_LP_VFP_DISABLE;
  VidCfg.LPVerticalBackPorchEnable = DSI_LP_VBP_DISABLE;
  VidCfg.LPVerticalSyncActiveEnable = DSI_LP_VSYNC_DISABLE;
  VidCfg.FrameBTAAcknowledgeEnable = DSI_FBTAA_DISABLE;
  if (HAL_DSI_ConfigVideoMode(&hdsi, &VidCfg) != HAL_OK)
  {
    _Error_Handler(__FILE__, __LINE__);
  }

  if (HAL_DSI_SetGenericVCID(&hdsi, 0) != HAL_OK)
  {
    _Error_Handler(__FILE__, __LINE__);
  }

}

/* I2C1 init function */
static void MX_I2C1_Init(void)
{

  hi2c1.Instance = I2C1;
  hi2c1.Init.ClockSpeed = 100000;
  hi2c1.Init.DutyCycle = I2C_DUTYCYCLE_2;
  hi2c1.Init.OwnAddress1 = 0;
  hi2c1.Init.AddressingMode = I2C_ADDRESSINGMODE_7BIT;
  hi2c1.Init.DualAddressMode = I2C_DUALADDRESS_DISABLE;
  hi2c1.Init.OwnAddress2 = 0;
  hi2c1.Init.GeneralCallMode = I2C_GENERALCALL_DISABLE;
  hi2c1.Init.NoStretchMode = I2C_NOSTRETCH_DISABLE;
  if (HAL_I2C_Init(&hi2c1) != HAL_OK)
  {
    _Error_Handler(__FILE__, __LINE__);
  }

}

/* LTDC init function */
static void MX_LTDC_Init(void)
{

  LTDC_LayerCfgTypeDef pLayerCfg;
  LTDC_LayerCfgTypeDef pLayerCfg1;

  hltdc.Instance = LTDC;
  hltdc.Init.HSPolarity = LTDC_HSPOLARITY_AL;
  hltdc.Init.VSPolarity = LTDC_VSPOLARITY_AL;
  hltdc.Init.DEPolarity = LTDC_DEPOLARITY_AL;
  hltdc.Init.PCPolarity = LTDC_PCPOLARITY_IPC;
  hltdc.Init.HorizontalSync = 7;
  hltdc.Init.VerticalSync = 3;
  hltdc.Init.AccumulatedHBP = 14;
  hltdc.Init.AccumulatedVBP = 5;
  hltdc.Init.AccumulatedActiveW = 654;
  hltdc.Init.AccumulatedActiveH = 485;
  hltdc.Init.TotalWidth = 660;
  hltdc.Init.TotalHeigh = 487;
  hltdc.Init.Backcolor.Blue = 0;
  hltdc.Init.Backcolor.Green = 0;
  hltdc.Init.Backcolor.Red = 0;
  if (HAL_LTDC_Init(&hltdc) != HAL_OK)
  {
    _Error_Handler(__FILE__, __LINE__);
  }

  pLayerCfg.WindowX0 = 0;
  pLayerCfg.WindowX1 = 0;
  pLayerCfg.WindowY0 = 0;
  pLayerCfg.WindowY1 = 0;
  pLayerCfg.PixelFormat = LTDC_PIXEL_FORMAT_ARGB8888;
  pLayerCfg.Alpha = 0;
  pLayerCfg.Alpha0 = 0;
  pLayerCfg.BlendingFactor1 = LTDC_BLENDING_FACTOR1_CA;
  pLayerCfg.BlendingFactor2 = LTDC_BLENDING_FACTOR2_CA;
  pLayerCfg.FBStartAdress = 0;
  pLayerCfg.ImageWidth = 0;
  pLayerCfg.ImageHeight = 0;
  pLayerCfg.Backcolor.Blue = 0;
  pLayerCfg.Backcolor.Green = 0;
  pLayerCfg.Backcolor.Red = 0;
  if (HAL_LTDC_ConfigLayer(&hltdc, &pLayerCfg, 0) != HAL_OK)
  {
    _Error_Handler(__FILE__, __LINE__);
  }

  pLayerCfg1.WindowX0 = 0;
  pLayerCfg1.WindowX1 = 0;
  pLayerCfg1.WindowY0 = 0;
  pLayerCfg1.WindowY1 = 0;
  pLayerCfg1.PixelFormat = LTDC_PIXEL_FORMAT_ARGB8888;
  pLayerCfg1.Alpha = 0;
  pLayerCfg1.Alpha0 = 0;
  pLayerCfg1.BlendingFactor1 = LTDC_BLENDING_FACTOR1_CA;
  pLayerCfg1.BlendingFactor2 = LTDC_BLENDING_FACTOR2_CA;
  pLayerCfg1.FBStartAdress = 0;
  pLayerCfg1.ImageWidth = 0;
  pLayerCfg1.ImageHeight = 0;
  pLayerCfg1.Backcolor.Blue = 0;
  pLayerCfg1.Backcolor.Green = 0;
  pLayerCfg1.Backcolor.Red = 0;
  if (HAL_LTDC_ConfigLayer(&hltdc, &pLayerCfg1, 1) != HAL_OK)
  {
    _Error_Handler(__FILE__, __LINE__);
  }

}

/* USART3 init function */
static void MX_USART3_UART_Init(void)
{

  huart3.Instance = USART3;
  huart3.Init.BaudRate = 115200;
  huart3.Init.WordLength = UART_WORDLENGTH_8B;
  huart3.Init.StopBits = UART_STOPBITS_1;
  huart3.Init.Parity = UART_PARITY_NONE;
  huart3.Init.Mode = UART_MODE_TX_RX;
  huart3.Init.HwFlowCtl = UART_HWCONTROL_NONE;
  huart3.Init.OverSampling = UART_OVERSAMPLING_16;
  if (HAL_UART_Init(&huart3) != HAL_OK)
  {
    _Error_Handler(__FILE__, __LINE__);
  }

}

/* FMC initialization function */
static void MX_FMC_Init(void)
{
  FMC_SDRAM_TimingTypeDef SdramTiming;

  /** Perform the SDRAM1 memory initialization sequence
  */
  hsdram1.Instance = FMC_SDRAM_DEVICE;
  /* hsdram1.Init */
  hsdram1.Init.SDBank = FMC_SDRAM_BANK2;
  hsdram1.Init.ColumnBitsNumber = FMC_SDRAM_COLUMN_BITS_NUM_8;
  hsdram1.Init.RowBitsNumber = FMC_SDRAM_ROW_BITS_NUM_12;
  hsdram1.Init.MemoryDataWidth = FMC_SDRAM_MEM_BUS_WIDTH_16;
  hsdram1.Init.InternalBankNumber = FMC_SDRAM_INTERN_BANKS_NUM_4;
  hsdram1.Init.CASLatency = FMC_SDRAM_CAS_LATENCY_1;
  hsdram1.Init.WriteProtection = FMC_SDRAM_WRITE_PROTECTION_DISABLE;
  hsdram1.Init.SDClockPeriod = FMC_SDRAM_CLOCK_DISABLE;
  hsdram1.Init.ReadBurst = FMC_SDRAM_RBURST_DISABLE;
  hsdram1.Init.ReadPipeDelay = FMC_SDRAM_RPIPE_DELAY_0;
  /* SdramTiming */
  SdramTiming.LoadToActiveDelay = 16;
  SdramTiming.ExitSelfRefreshDelay = 16;
  SdramTiming.SelfRefreshTime = 16;
  SdramTiming.RowCycleDelay = 16;
  SdramTiming.WriteRecoveryTime = 16;
  SdramTiming.RPDelay = 16;
  SdramTiming.RCDDelay = 16;

  if (HAL_SDRAM_Init(&hsdram1, &SdramTiming) != HAL_OK)
  {
    _Error_Handler(__FILE__, __LINE__);
  }

}

/** Configure pins
     PE4   ------> SAI1_FS_A
     PG14   ------> USART6_TX
     PB3   ------> I2S3_CK
     PC12   ------> SDIO_CK
     PE5   ------> SAI1_SCK_A
     PB6   ------> QUADSPI_BK1_NCS
     PD6   ------> SAI1_SD_A
     PC11   ------> SDIO_D3
     PC10   ------> SDIO_D2
     PA12   ------> USB_OTG_FS_DP
     PA11   ------> USB_OTG_FS_DM
     PG9   ------> USART6_RX
     PD2   ------> SDIO_CMD
     PA10   ------> USB_OTG_FS_ID
     PA9   ------> USB_OTG_FS_VBUS
     PC9   ------> SDIO_D1
     PC8   ------> SDIO_D0
     PH4   ------> I2C2_SCL
     PH5   ------> I2C2_SDA
     PG7   ------> SAI1_MCLK_A
     PF7   ------> QUADSPI_BK1_IO2
     PF6   ------> QUADSPI_BK1_IO3
     PF10   ------> QUADSPI_CLK
     PF9   ------> QUADSPI_BK1_IO1
     PF8   ------> QUADSPI_BK1_IO0
     PD13   ------> S_TIM4_CH2
*/
static void MX_GPIO_Init(void)
{

  GPIO_InitTypeDef GPIO_InitStruct;

  /* GPIO Ports Clock Enable */
  __HAL_RCC_GPIOE_CLK_ENABLE();
  __HAL_RCC_GPIOG_CLK_ENABLE();
  __HAL_RCC_GPIOB_CLK_ENABLE();
  __HAL_RCC_GPIOC_CLK_ENABLE();
  __HAL_RCC_GPIOA_CLK_ENABLE();
  __HAL_RCC_GPIOD_CLK_ENABLE();
  __HAL_RCC_GPIOI_CLK_ENABLE();
  __HAL_RCC_GPIOF_CLK_ENABLE();
  __HAL_RCC_GPIOK_CLK_ENABLE();
  __HAL_RCC_GPIOH_CLK_ENABLE();
  __HAL_RCC_GPIOJ_CLK_ENABLE();

  /*Configure GPIO pin Output Level */
  HAL_GPIO_WritePin(GPIOE, SPKR_HP_Pin|AUDIO_RST_Pin, GPIO_PIN_RESET);

  /*Configure GPIO pin Output Level */
  HAL_GPIO_WritePin(GPIOD, LED3_Pin|LED2_Pin, GPIO_PIN_RESET);

  /*Configure GPIO pin Output Level */
  HAL_GPIO_WritePin(LED4_GPIO_Port, LED4_Pin, GPIO_PIN_RESET);

  /*Configure GPIO pin Output Level */
  HAL_GPIO_WritePin(LED1_GPIO_Port, LED1_Pin, GPIO_PIN_RESET);

  /*Configure GPIO pin Output Level */
  HAL_GPIO_WritePin(GPIOC, WR_Pin|RCK_Pin|WRST_Pin|RRST_Pin, GPIO_PIN_RESET);

  /*Configure GPIO pin Output Level */
  HAL_GPIO_WritePin(GPIOB, OTG_FS1_PowerSwitchOn_Pin|EXT_RESET_Pin|SIOC_Pin, GPIO_PIN_RESET);

  /*Configure GPIO pin Output Level */
  HAL_GPIO_WritePin(GPIOA, SIOD_Pin|LCD_BL_CTRL_Pin, GPIO_PIN_RESET);

  /*Configure GPIO pins : SAI1_FSA_Pin SAI1_SCKA_Pin */
  GPIO_InitStruct.Pin = SAI1_FSA_Pin|SAI1_SCKA_Pin;
  GPIO_InitStruct.Mode = GPIO_MODE_AF_PP;
  GPIO_InitStruct.Pull = GPIO_NOPULL;
  GPIO_InitStruct.Speed = GPIO_SPEED_FREQ_LOW;
  GPIO_InitStruct.Alternate = GPIO_AF6_SAI1;
  HAL_GPIO_Init(GPIOE, &GPIO_InitStruct);

  /*Configure GPIO pins : SPKR_HP_Pin AUDIO_RST_Pin */
  GPIO_InitStruct.Pin = SPKR_HP_Pin|AUDIO_RST_Pin;
  GPIO_InitStruct.Mode = GPIO_MODE_OUTPUT_PP;
  GPIO_InitStruct.Pull = GPIO_NOPULL;
  GPIO_InitStruct.Speed = GPIO_SPEED_FREQ_LOW;
  HAL_GPIO_Init(GPIOE, &GPIO_InitStruct);

  /*Configure GPIO pins : ARDUINO_USART6_TX_Pin USART6_RX_Pin */
  GPIO_InitStruct.Pin = ARDUINO_USART6_TX_Pin|USART6_RX_Pin;
  GPIO_InitStruct.Mode = GPIO_MODE_AF_PP;
  GPIO_InitStruct.Pull = GPIO_NOPULL;
  GPIO_InitStruct.Speed = GPIO_SPEED_FREQ_VERY_HIGH;
  GPIO_InitStruct.Alternate = GPIO_AF8_USART6;
  HAL_GPIO_Init(GPIOG, &GPIO_InitStruct);

  /*Configure GPIO pin : I2S3_CK_Pin */
  GPIO_InitStruct.Pin = I2S3_CK_Pin;
  GPIO_InitStruct.Mode = GPIO_MODE_AF_PP;
  GPIO_InitStruct.Pull = GPIO_NOPULL;
  GPIO_InitStruct.Speed = GPIO_SPEED_FREQ_LOW;
  GPIO_InitStruct.Alternate = GPIO_AF6_SPI3;
  HAL_GPIO_Init(I2S3_CK_GPIO_Port, &GPIO_InitStruct);

  /*Configure GPIO pins : uSD_CLK_Pin uSD_D3_Pin uSD_D2_Pin uSD_D1_Pin
                           uSD_D0_Pin */
  GPIO_InitStruct.Pin = uSD_CLK_Pin|uSD_D3_Pin|uSD_D2_Pin|uSD_D1_Pin
                          |uSD_D0_Pin;
  GPIO_InitStruct.Mode = GPIO_MODE_AF_PP;
  GPIO_InitStruct.Pull = GPIO_NOPULL;
  GPIO_InitStruct.Speed = GPIO_SPEED_FREQ_VERY_HIGH;
  GPIO_InitStruct.Alternate = GPIO_AF12_SDIO;
  HAL_GPIO_Init(GPIOC, &GPIO_InitStruct);

  /*Configure GPIO pins : Data0_Pin Data5_Pin Data2_Pin Data6_Pin
                           uSD_Detect_Pin */
  GPIO_InitStruct.Pin = Data0_Pin|Data5_Pin|Data2_Pin|Data6_Pin
                          |uSD_Detect_Pin;
  GPIO_InitStruct.Mode = GPIO_MODE_INPUT;
  GPIO_InitStruct.Pull = GPIO_NOPULL;
  HAL_GPIO_Init(GPIOG, &GPIO_InitStruct);

  /*Configure GPIO pin : OTG_FS1_OverCurrent_Pin */
  GPIO_InitStruct.Pin = OTG_FS1_OverCurrent_Pin;
  GPIO_InitStruct.Mode = GPIO_MODE_IT_RISING;
  GPIO_InitStruct.Pull = GPIO_NOPULL;
  HAL_GPIO_Init(OTG_FS1_OverCurrent_GPIO_Port, &GPIO_InitStruct);

  /*Configure GPIO pin : QSPI_BK1_NCS_Pin */
  GPIO_InitStruct.Pin = QSPI_BK1_NCS_Pin;
  GPIO_InitStruct.Mode = GPIO_MODE_AF_PP;
  GPIO_InitStruct.Pull = GPIO_NOPULL;
  GPIO_InitStruct.Speed = GPIO_SPEED_FREQ_VERY_HIGH;
  GPIO_InitStruct.Alternate = GPIO_AF10_QSPI;
  HAL_GPIO_Init(QSPI_BK1_NCS_GPIO_Port, &GPIO_InitStruct);

  /*Configure GPIO pin : MIC_DATA_Pin */
  GPIO_InitStruct.Pin = MIC_DATA_Pin;
  GPIO_InitStruct.Mode = GPIO_MODE_AF_PP;
  GPIO_InitStruct.Pull = GPIO_NOPULL;
  GPIO_InitStruct.Speed = GPIO_SPEED_FREQ_LOW;
  GPIO_InitStruct.Alternate = GPIO_AF6_SAI1;
  HAL_GPIO_Init(MIC_DATA_GPIO_Port, &GPIO_InitStruct);

  /*Configure GPIO pins : USB_FS1_P_Pin USB_FS1_N_Pin USB_FS1_ID_Pin */
  GPIO_InitStruct.Pin = USB_FS1_P_Pin|USB_FS1_N_Pin|USB_FS1_ID_Pin;
  GPIO_InitStruct.Mode = GPIO_MODE_AF_PP;
  GPIO_InitStruct.Pull = GPIO_NOPULL;
  GPIO_InitStruct.Speed = GPIO_SPEED_FREQ_VERY_HIGH;
  GPIO_InitStruct.Alternate = GPIO_AF10_OTG_FS;
  HAL_GPIO_Init(GPIOA, &GPIO_InitStruct);

  /*Configure GPIO pins : LED3_Pin LED2_Pin */
  GPIO_InitStruct.Pin = LED3_Pin|LED2_Pin;
  GPIO_InitStruct.Mode = GPIO_MODE_OUTPUT_OD;
  GPIO_InitStruct.Pull = GPIO_NOPULL;
  GPIO_InitStruct.Speed = GPIO_SPEED_FREQ_LOW;
  HAL_GPIO_Init(GPIOD, &GPIO_InitStruct);

  /*Configure GPIO pin : LED4_Pin */
  GPIO_InitStruct.Pin = LED4_Pin;
  GPIO_InitStruct.Mode = GPIO_MODE_OUTPUT_OD;
  GPIO_InitStruct.Pull = GPIO_NOPULL;
  GPIO_InitStruct.Speed = GPIO_SPEED_FREQ_LOW;
  HAL_GPIO_Init(LED4_GPIO_Port, &GPIO_InitStruct);

  /*Configure GPIO pin : uSD_CMD_Pin */
  GPIO_InitStruct.Pin = uSD_CMD_Pin;
  GPIO_InitStruct.Mode = GPIO_MODE_AF_PP;
  GPIO_InitStruct.Pull = GPIO_NOPULL;
  GPIO_InitStruct.Speed = GPIO_SPEED_FREQ_VERY_HIGH;
  GPIO_InitStruct.Alternate = GPIO_AF12_SDIO;
  HAL_GPIO_Init(uSD_CMD_GPIO_Port, &GPIO_InitStruct);

  /*Configure GPIO pin : VBUS_FS1_Pin */
  GPIO_InitStruct.Pin = VBUS_FS1_Pin;
  GPIO_InitStruct.Mode = GPIO_MODE_AF_PP;
  GPIO_InitStruct.Pull = GPIO_NOPULL;
  HAL_GPIO_Init(VBUS_FS1_GPIO_Port, &GPIO_InitStruct);

  /*Configure GPIO pins : I2C2_SCL_Pin I2C2_SDA_Pin */
  GPIO_InitStruct.Pin = I2C2_SCL_Pin|I2C2_SDA_Pin;
  GPIO_InitStruct.Mode = GPIO_MODE_AF_OD;
  GPIO_InitStruct.Pull = GPIO_PULLUP;
  GPIO_InitStruct.Speed = GPIO_SPEED_FREQ_VERY_HIGH;
  GPIO_InitStruct.Alternate = GPIO_AF4_I2C2;
  HAL_GPIO_Init(GPIOH, &GPIO_InitStruct);

  /*Configure GPIO pin : SAI1_MCLKA_Pin */
  GPIO_InitStruct.Pin = SAI1_MCLKA_Pin;
  GPIO_InitStruct.Mode = GPIO_MODE_AF_PP;
  GPIO_InitStruct.Pull = GPIO_NOPULL;
  GPIO_InitStruct.Speed = GPIO_SPEED_FREQ_LOW;
  GPIO_InitStruct.Alternate = GPIO_AF6_SAI1;
  HAL_GPIO_Init(SAI1_MCLKA_GPIO_Port, &GPIO_InitStruct);

  /*Configure GPIO pin : LED1_Pin */
  GPIO_InitStruct.Pin = LED1_Pin;
  GPIO_InitStruct.Mode = GPIO_MODE_OUTPUT_OD;
  GPIO_InitStruct.Pull = GPIO_NOPULL;
  GPIO_InitStruct.Speed = GPIO_SPEED_FREQ_LOW;
  HAL_GPIO_Init(LED1_GPIO_Port, &GPIO_InitStruct);

  /*Configure GPIO pins : QSPI_BK1_IO2_Pin QSPI_BK1_IO3_Pin QSPI_CLK_Pin */
  GPIO_InitStruct.Pin = QSPI_BK1_IO2_Pin|QSPI_BK1_IO3_Pin|QSPI_CLK_Pin;
  GPIO_InitStruct.Mode = GPIO_MODE_AF_PP;
  GPIO_InitStruct.Pull = GPIO_NOPULL;
  GPIO_InitStruct.Speed = GPIO_SPEED_FREQ_VERY_HIGH;
  GPIO_InitStruct.Alternate = GPIO_AF9_QSPI;
  HAL_GPIO_Init(GPIOF, &GPIO_InitStruct);

  /*Configure GPIO pins : QSPI_BK1_IO1_Pin QSPI_BK1_IO0_Pin */
  GPIO_InitStruct.Pin = QSPI_BK1_IO1_Pin|QSPI_BK1_IO0_Pin;
  GPIO_InitStruct.Mode = GPIO_MODE_AF_PP;
  GPIO_InitStruct.Pull = GPIO_NOPULL;
  GPIO_InitStruct.Speed = GPIO_SPEED_FREQ_VERY_HIGH;
  GPIO_InitStruct.Alternate = GPIO_AF10_QSPI;
  HAL_GPIO_Init(GPIOF, &GPIO_InitStruct);

  /*Configure GPIO pins : WR_Pin RCK_Pin WRST_Pin RRST_Pin */
  GPIO_InitStruct.Pin = WR_Pin|RCK_Pin|WRST_Pin|RRST_Pin;
  GPIO_InitStruct.Mode = GPIO_MODE_OUTPUT_PP;
  GPIO_InitStruct.Pull = GPIO_NOPULL;
  GPIO_InitStruct.Speed = GPIO_SPEED_FREQ_HIGH;
  HAL_GPIO_Init(GPIOC, &GPIO_InitStruct);

  /*Configure GPIO pins : OTG_FS1_PowerSwitchOn_Pin EXT_RESET_Pin */
  GPIO_InitStruct.Pin = OTG_FS1_PowerSwitchOn_Pin|EXT_RESET_Pin;
  GPIO_InitStruct.Mode = GPIO_MODE_OUTPUT_PP;
  GPIO_InitStruct.Pull = GPIO_NOPULL;
  GPIO_InitStruct.Speed = GPIO_SPEED_FREQ_LOW;
  HAL_GPIO_Init(GPIOB, &GPIO_InitStruct);

  /*Configure GPIO pin : MIC_CK_Pin */
  GPIO_InitStruct.Pin = MIC_CK_Pin;
  GPIO_InitStruct.Mode = GPIO_MODE_AF_PP;
  GPIO_InitStruct.Pull = GPIO_NOPULL;
  GPIO_InitStruct.Speed = GPIO_SPEED_FREQ_LOW;
  GPIO_InitStruct.Alternate = GPIO_AF2_TIM4;
  HAL_GPIO_Init(MIC_CK_GPIO_Port, &GPIO_InitStruct);

  /*Configure GPIO pin : LCD_INT_Pin */
  GPIO_InitStruct.Pin = LCD_INT_Pin;
  GPIO_InitStruct.Mode = GPIO_MODE_IT_RISING;
  GPIO_InitStruct.Pull = GPIO_NOPULL;
  HAL_GPIO_Init(LCD_INT_GPIO_Port, &GPIO_InitStruct);

  /*Configure GPIO pins : Data1_Pin Data3_Pin Data4_Pin Data7_Pin */
  GPIO_InitStruct.Pin = Data1_Pin|Data3_Pin|Data4_Pin|Data7_Pin;
  GPIO_InitStruct.Mode = GPIO_MODE_INPUT;
  GPIO_InitStruct.Pull = GPIO_NOPULL;
  HAL_GPIO_Init(GPIOA, &GPIO_InitStruct);

  /*Configure GPIO pin : SIOD_Pin */
  GPIO_InitStruct.Pin = SIOD_Pin;
  GPIO_InitStruct.Mode = GPIO_MODE_OUTPUT_OD;
  GPIO_InitStruct.Pull = GPIO_PULLUP;
  GPIO_InitStruct.Speed = GPIO_SPEED_FREQ_HIGH;
  HAL_GPIO_Init(SIOD_GPIO_Port, &GPIO_InitStruct);

  /*Configure GPIO pin : LCD_BL_CTRL_Pin */
  GPIO_InitStruct.Pin = LCD_BL_CTRL_Pin;
  GPIO_InitStruct.Mode = GPIO_MODE_OUTPUT_PP;
  GPIO_InitStruct.Pull = GPIO_NOPULL;
  GPIO_InitStruct.Speed = GPIO_SPEED_FREQ_LOW;
  HAL_GPIO_Init(LCD_BL_CTRL_GPIO_Port, &GPIO_InitStruct);

  /*Configure GPIO pin : VSYNC_Pin */
  GPIO_InitStruct.Pin = VSYNC_Pin;
  GPIO_InitStruct.Mode = GPIO_MODE_IT_FALLING;
  GPIO_InitStruct.Pull = GPIO_NOPULL;
  HAL_GPIO_Init(VSYNC_GPIO_Port, &GPIO_InitStruct);

  /*Configure GPIO pin : SIOC_Pin */
  GPIO_InitStruct.Pin = SIOC_Pin;
  GPIO_InitStruct.Mode = GPIO_MODE_OUTPUT_OD;
  GPIO_InitStruct.Pull = GPIO_PULLUP;
  GPIO_InitStruct.Speed = GPIO_SPEED_FREQ_HIGH;
  HAL_GPIO_Init(SIOC_GPIO_Port, &GPIO_InitStruct);

  /* EXTI interrupt init*/
  HAL_NVIC_SetPriority(EXTI1_IRQn, 0, 0);
  HAL_NVIC_EnableIRQ(EXTI1_IRQn);

}

/* USER CODE BEGIN 4 */
void HAL_GPIO_EXTI_Callback(uint16_t GPIO_Pin)
{
	if(GPIO_Pin==VSYNC_Pin)
	{
		if(vsyncStatus==0)
		{
			//WE_L();
			WE_H();
			photoTakeTimeStart=HAL_GetTick();
			vsyncStatus=1;
		}
		else if(vsyncStatus==1)
		{
			//WE_H();
			WE_L();
			photoTakeTimeEnd=HAL_GetTick();
			photoTakeTimeElapse=photoTakeTimeEnd-photoTakeTimeStart;
			vsyncStatus=2;
		}
	}
}

/* USER CODE END 4 */

void _Error_Handler(char *file, int line)
{
  while(1)
  {
  }
}

/************************ (C) COPYRIGHT STMicroelectronics *****END OF FILE****/
